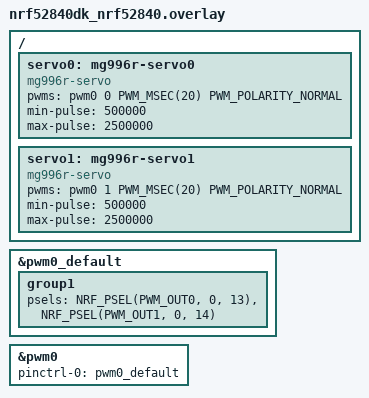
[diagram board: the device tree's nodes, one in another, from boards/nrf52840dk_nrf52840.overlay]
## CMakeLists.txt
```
# SPDX-License-Identifier: Apache-2.0

cmake_minimum_required(VERSION 3.20.0)
find_package(Zephyr REQUIRED HINTS $ENV{ZEPHYR_BASE})
project(app_motor_test)

target_sources(app PRIVATE src/main.c)
```

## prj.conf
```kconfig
CONFIG_STDOUT_CONSOLE=y
CONFIG_LOG=y
CONFIG_PRINTK=y
CONFIG_PWM=y
CONFIG_SERVO=y
CONFIG_MG996R=y
CONFIG_SHELL=y
```

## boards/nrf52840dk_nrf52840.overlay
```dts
/* SPDX-License-Identifier: Apache-2.0 */

/ {
    servo0: mg996r-servo0 {
        status = "okay";
        compatible = "mg996r-servo";
        pwms = <&pwm0 0 PWM_MSEC(20) PWM_POLARITY_NORMAL>;
        min-pulse = <500000>;
        max-pulse = <2500000>;
    };

    servo1: mg996r-servo1 {
        status = "okay";
        compatible = "mg996r-servo";
        pwms = <&pwm0 1 PWM_MSEC(20) PWM_POLARITY_NORMAL>;
        min-pulse = <500000>;
        max-pulse = <2500000>;
    };
};

/* Add pin 14 to pwm0 controller */
&pwm0_default {
    group1 {
        psels = <NRF_PSEL(PWM_OUT0, 0, 13)>,
                <NRF_PSEL(PWM_OUT1, 0, 14)>;
    };
};

/* PWM0 configuration for servo0 */
&pwm0 {
    status = "okay";
    pinctrl-0 = <&pwm0_default>;
};
```

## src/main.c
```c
/*
 * SPDX-License-Identifier: Apache-2.0
 */

#include <zephyr/kernel.h>
#include <zephyr/sys/printk.h>
#include <zephyr/device.h>
#include <zephyr/devicetree.h>
#include <app/drivers/mg996r.h>

static const struct device *servo0 = DEVICE_DT_GET(DT_NODELABEL(servo0));
static const struct device *servo1 = DEVICE_DT_GET(DT_NODELABEL(servo1));

#define STEP 5 /* Step in degrees */

enum direction {
	DOWN,
	UP,
};

int main(void)
{
	int ret;
	int degrees = 0;
	enum direction dir = UP;

	printk("Servomotor control\n");

	if (!device_is_ready(servo0)) {
		printk("Error: servo0 device is not ready\n");
		return 0;
	}

	if (!device_is_ready(servo1)) {
		printk("Error: servo0 device is not ready\n");
		return 0;
	}

	while (1) {
		printk("Setting degrees: %d\n", degrees);

		ret = mg996r_set_angle(servo0, degrees);
		if (ret) {
			printk("Error setting mg996r angle! (ret = %d)", ret);
		}

		ret = mg996r_set_angle(servo1, degrees);
		if (ret) {
			printk("Error setting mg996r angle! (ret = %d)", ret);
		}

		/* Rotate back and forth */
		if (dir == DOWN) {
			if (degrees <= MG996R_MIN_ANGLE) {
				dir = UP;
				degrees = MG996R_MIN_ANGLE;
			} else {
				degrees -= STEP;
			}
		} else {
			degrees += STEP;

			if (degrees >= MG996R_MAX_ANGLE) {
				dir = DOWN;
				degrees = MG996R_MAX_ANGLE;
			}
		}

		k_sleep(K_MSEC(50));
	}

	return 0;
}
```
